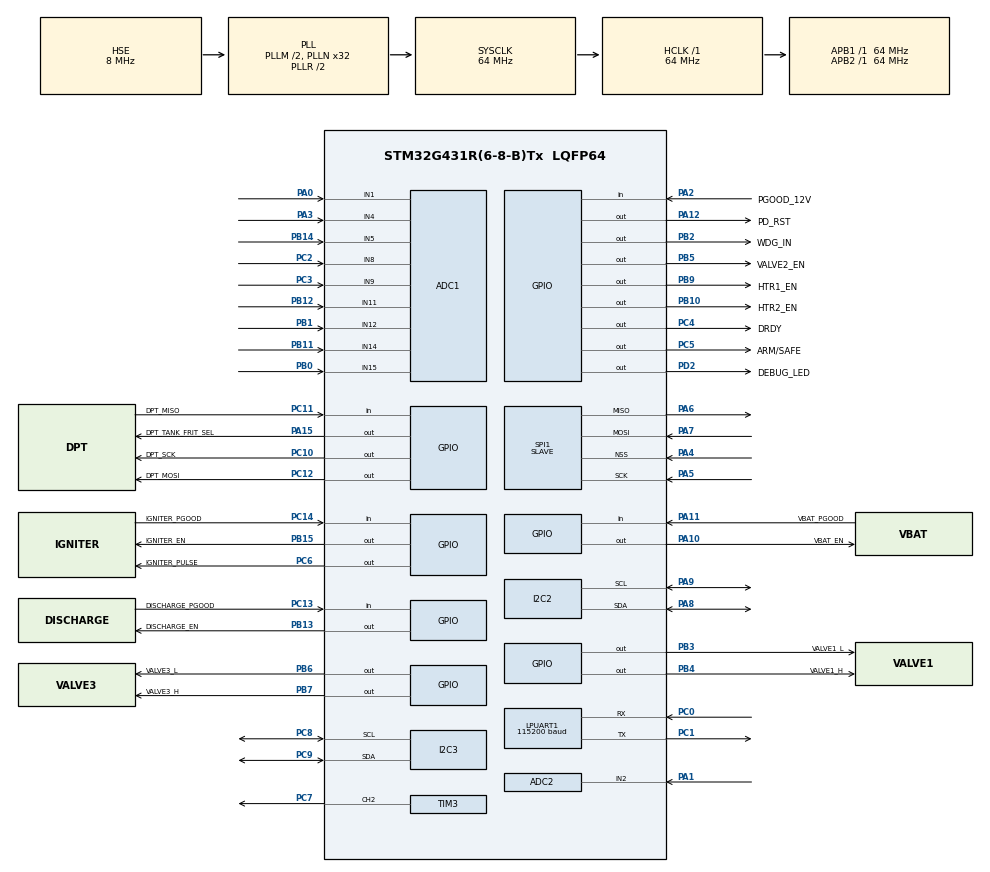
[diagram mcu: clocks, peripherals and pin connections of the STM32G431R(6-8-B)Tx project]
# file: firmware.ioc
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ADC1.Channel-0\#ChannelRegularConversion=ADC_CHANNEL_1
ADC1.ContinuousConvMode=ENABLE
ADC1.DMAAccessModeView=ENABLE
ADC1.EnableInjectedConversion=ENABLE
ADC1.InjNumberOfConversion=1
ADC1.InjectedChannel-1\#ChannelInjectedConversion=ADC_CHANNEL_4
ADC1.InjectedOffsetNumber-1\#ChannelInjectedConversion=ADC_OFFSET_NONE
ADC1.InjectedRank-1\#ChannelInjectedConversion=1
ADC1.InjectedSamplingTime-1\#ChannelInjectedConversion=ADC_SAMPLETIME_92CYCLES_5
ADC1.Mode=ADC_DUALMODE_REGSIMULT
ADC1.NbrOfConversion=1
ADC1.NbrOfConversionFlag=1
ADC1.OffsetNumber-0\#ChannelRegularConversion=ADC_OFFSET_NONE
ADC1.Rank-0\#ChannelRegularConversion=1
ADC1.Rank1_Channel=ADC_CHANNEL_4
ADC1.Rank2_Channel=ADC_CHANNEL_1
ADC1.Rank3_Channel=ADC_CHANNEL_1
ADC1.Rank4_Channel=ADC_CHANNEL_1
ADC1.SamplingTime-0\#ChannelRegularConversion=ADC_SAMPLETIME_2CYCLES_5
ADC1.master=1
ADC2.Channel-0\#ChannelRegularConversion=ADC_CHANNEL_2
ADC2.ClockPrescaler=ADC_CLOCK_SYNC_PCLK_DIV2
ADC2.ContinuousConvMode=ENABLE
ADC2.DMAAccessModeView=ENABLE
ADC2.Mode=ADC_DUALMODE_REGSIMULT
ADC2.NbrOfConversionFlag=1
ADC2.OffsetNumber-0\#ChannelRegularConversion=ADC_OFFSET_NONE
ADC2.Rank-0\#ChannelRegularConversion=1
ADC2.SamplingTime-0\#ChannelRegularConversion=ADC_SAMPLETIME_2CYCLES_5
Dma.ADC1.0.Direction=DMA_PERIPH_TO_MEMORY
Dma.ADC1.0.EventEnable=DISABLE
Dma.ADC1.0.Instance=DMA1_Channel1
Dma.ADC1.0.MemDataAlignment=DMA_MDATAALIGN_WORD
Dma.ADC1.0.MemInc=DMA_MINC_ENABLE
Dma.ADC1.0.Mode=DMA_NORMAL
Dma.ADC1.0.PeriphDataAlignment=DMA_PDATAALIGN_WORD
Dma.ADC1.0.PeriphInc=DMA_PINC_DISABLE
Dma.ADC1.0.Polarity=HAL_DMAMUX_REQ_GEN_RISING
Dma.ADC1.0.Priority=DMA_PRIORITY_VERY_HIGH
Dma.ADC1.0.RequestNumber=1
Dma.ADC1.0.SignalID=NONE
Dma.ADC1.0.SyncEnable=DISABLE
Dma.ADC1.0.SyncPolarity=HAL_DMAMUX_SYNC_NO_EVENT
Dma.ADC1.0.SyncRequestNumber=1
Dma.ADC1.0.SyncSignalID=NONE
Dma.Request0=ADC1
Dma.Request1=SPI1_RX
Dma.Request2=SPI1_TX
Dma.SPI1_RX.1.Direction=DMA_PERIPH_TO_MEMORY
Dma.SPI1_RX.1.EventEnable=DISABLE
Dma.SPI1_RX.1.Instance=DMA1_Channel2
Dma.SPI1_RX.1.MemDataAlignment=DMA_MDATAALIGN_BYTE
Dma.SPI1_RX.1.MemInc=DMA_MINC_ENABLE
Dma.SPI1_RX.1.Mode=DMA_NORMAL
Dma.SPI1_RX.1.PeriphDataAlignment=DMA_PDATAALIGN_BYTE
Dma.SPI1_RX.1.PeriphInc=DMA_PINC_DISABLE
Dma.SPI1_RX.1.Polarity=HAL_DMAMUX_REQ_GEN_RISING
Dma.SPI1_RX.1.Priority=DMA_PRIORITY_HIGH
Dma.SPI1_RX.1.RequestNumber=1
Dma.SPI1_RX.1.SignalID=NONE
Dma.SPI1_RX.1.SyncEnable=DISABLE
Dma.SPI1_RX.1.SyncPolarity=HAL_DMAMUX_SYNC_NO_EVENT
Dma.SPI1_RX.1.SyncRequestNumber=1
Dma.SPI1_RX.1.SyncSignalID=NONE
Dma.SPI1_TX.2.Direction=DMA_MEMORY_TO_PERIPH
Dma.SPI1_TX.2.EventEnable=DISABLE
Dma.SPI1_TX.2.Instance=DMA1_Channel3
Dma.SPI1_TX.2.MemDataAlignment=DMA_MDATAALIGN_BYTE
Dma.SPI1_TX.2.MemInc=DMA_MINC_ENABLE
Dma.SPI1_TX.2.Mode=DMA_NORMAL
Dma.SPI1_TX.2.PeriphDataAlignment=DMA_PDATAALIGN_BYTE
Dma.SPI1_TX.2.PeriphInc=DMA_PINC_DISABLE
Dma.SPI1_TX.2.Polarity=HAL_DMAMUX_REQ_GEN_RISING
Dma.SPI1_TX.2.Priority=DMA_PRIORITY_HIGH
Dma.SPI1_TX.2.RequestNumber=1
Dma.SPI1_TX.2.SignalID=NONE
Dma.SPI1_TX.2.SyncEnable=DISABLE
Dma.SPI1_TX.2.SyncPolarity=HAL_DMAMUX_SYNC_NO_EVENT
Dma.SPI1_TX.2.SyncRequestNumber=1
Dma.SPI1_TX.2.SyncSignalID=NONE
I2C2.Timing=0x10B17DB5
I2C3.Timing=0x10B17DB5
LPUART1.BaudRate=115200
Mcu.Family=STM32G4
Mcu.Name=STM32G431R(6-8-B)Tx
Mcu.Package=LQFP64
NVIC.DMA1_Channel1_IRQn=true\:0\:0\:false\:false\:true\:false\:true\:true
NVIC.DMA1_Channel2_IRQn=true\:0\:0\:false\:false\:true\:false\:true\:true
NVIC.DMA1_Channel3_IRQn=true\:0\:0\:false\:false\:true\:false\:true\:true
NVIC.I2C2_ER_IRQn=true\:0\:0\:false\:false\:true\:true\:true\:true
NVIC.I2C2_EV_IRQn=true\:0\:0\:false\:false\:true\:true\:true\:true
NVIC.PriorityGroup=NVIC_PRIORITYGROUP_4
NVIC.SPI1_IRQn=true\:0\:0\:false\:false\:true\:true\:true\:true
PA0.Mode=IN1-Single-Ended
PA0.Signal=ADC1_IN1
PA1.Mode=IN2-Single-Ended
PA1.Signal=ADC2_IN2
PA10.GPIO_Label=VBAT_EN
PA10.Signal=GPIO_Output
PA11.GPIO_Label=VBAT_PGOOD
PA11.Signal=GPIO_Input
PA12.GPIO_Label=PD_RST
PA12.Signal=GPIO_Output
PA13.Mode=Serial_Wire
PA13.Signal=SYS_JTMS-SWDIO
PA14.Mode=Serial_Wire
PA14.Signal=SYS_JTCK-SWCLK
PA15.GPIO_Label=DPT_TANK_FRIT_SEL
PA15.Signal=GPIO_Output
PA2.GPIO_Label=PGOOD_12V
PA2.Signal=GPIO_Input
PA3.Mode=IN4-Single-Ended
PA3.Signal=ADC1_IN4
PA4.Mode=NSS_Signal_Hard_Input
PA4.Signal=SPI1_NSS
PA5.Mode=Full_Duplex_Slave
PA5.Signal=SPI1_SCK
PA6.Mode=Full_Duplex_Slave
PA6.Signal=SPI1_MISO
PA7.Mode=Full_Duplex_Slave
PA7.Signal=SPI1_MOSI
PA8.Mode=I2C
PA8.Signal=I2C2_SDA
PA9.Mode=I2C
PA9.Signal=I2C2_SCL
PB0.Mode=IN15-Single-Ended
PB0.Signal=ADC1_IN15
PB1.Mode=IN12-Single-Ended
PB1.Signal=ADC1_IN12
PB10.GPIO_Label=HTR2_EN
PB10.Signal=GPIO_Output
PB11.Mode=IN14-Single-Ended
PB11.Signal=ADC1_IN14
PB12.Mode=IN11-Single-Ended
PB12.Signal=ADC1_IN11
PB13.GPIO_Label=DISCHARGE_EN
PB13.Signal=GPIO_Output
PB14.Mode=IN5-Single-Ended
PB14.Signal=ADC1_IN5
PB15.GPIO_Label=IGNITER_EN
PB15.Signal=GPIO_Output
PB2.GPIO_Label=WDG_IN
PB2.Signal=GPIO_Output
PB3.GPIO_Label=VALVE1_L
PB3.Signal=GPIO_Output
PB4.GPIO_Label=VALVE1_H
PB4.Signal=GPIO_Output
PB5.GPIO_Label=VALVE2_EN
PB5.Signal=GPIO_Output
PB6.GPIO_Label=VALVE3_L
PB6.Signal=GPIO_Output
PB7.GPIO_Label=VALVE3_H
PB7.Signal=GPIO_Output
PB9.GPIO_Label=HTR1_EN
PB9.Signal=GPIO_Output
PC0.Mode=Asynchronous
PC0.Signal=LPUART1_RX
PC1.Mode=Asynchronous
PC1.Signal=LPUART1_TX
PC10.GPIO_Label=DPT_SCK
PC10.Signal=GPIO_Output
PC11.GPIO_Label=DPT_MISO
PC11.Signal=GPIO_Input
PC12.GPIO_Label=DPT_MOSI
PC12.Signal=GPIO_Output
PC13.GPIO_Label=DISCHARGE_PGOOD
PC13.Signal=GPIO_Input
PC14-OSC32_IN.GPIO_Label=IGNITER_PGOOD
PC14-OSC32_IN.Signal=GPIO_Input
PC2.Mode=IN8-Single-Ended
PC2.Signal=ADC1_IN8
PC3.Mode=IN9-Single-Ended
PC3.Signal=ADC1_IN9
PC4.GPIO_Label=DRDY
PC4.Signal=GPIO_Output
PC5.GPIO_Label=ARM/SAFE
PC5.Signal=GPIO_Output
PC6.GPIO_Label=IGNITER_PULSE
PC6.Signal=GPIO_Output
PC7.Signal=S_TIM3_CH2
PC8.Mode=I2C
PC8.Signal=I2C3_SCL
PC9.Mode=I2C
PC9.Signal=I2C3_SDA
PD2.GPIO_Label=DEBUG_LED
PD2.Signal=GPIO_Output
PF0-OSC_IN.Mode=HSE-External-Oscillator
PF0-OSC_IN.Signal=RCC_OSC_IN
PF1-OSC_OUT.Mode=HSE-External-Oscillator
PF1-OSC_OUT.Signal=RCC_OSC_OUT
ProjectManager.HeapSize=0x200
ProjectManager.StackSize=0x400
ProjectManager.TargetToolchain=STM32CubeIDE
RCC.ADC12Freq_Value=64000000
RCC.AHBFreq_Value=64000000
RCC.APB1Freq_Value=64000000
RCC.APB1TimFreq_Value=64000000
RCC.APB2Freq_Value=64000000
RCC.APB2TimFreq_Value=64000000
RCC.CortexFreq_Value=64000000
RCC.EXTERNAL_CLOCK_VALUE=12288000
RCC.HCLKFreq_Value=64000000
RCC.HSE_VALUE=8000000
RCC.HSI48_VALUE=48000000
RCC.HSI_VALUE=16000000
RCC.LSE_VALUE=32768
RCC.PLLM=RCC_PLLM_DIV2
RCC.PLLN=32
RCC.PLLSourceVirtual=RCC_PLLSOURCE_HSE
RCC.SYSCLKFreq_VALUE=64000000
RCC.SYSCLKSource=RCC_SYSCLKSOURCE_PLLCLK
RCC.USBFreq_Value=64000000
RCC.VCOOutputFreq_Value=128000000
SH.S_TIM3_CH2.0=TIM3_CH2,Output Compare2 CH2
SPI1.DataSize=SPI_DATASIZE_8BIT
SPI1.Direction=SPI_DIRECTION_2LINES
SPI1.Mode=SPI_MODE_SLAVE
SPI1.VirtualNSS=VM_NSSHARD
SPI1.VirtualType=VM_SLAVE
TIM3.Channel-Output\ Compare2\ CH2=TIM_CHANNEL_2
TIM3.OCMode_2=TIM_OCMODE_TOGGLE
TIM3.PeriodNoDither=976
VP_ADC1_TempSens_Input.Mode=IN-TempSens
VP_ADC1_Vref_Input.Mode=IN-Vrefint
VP_SYS_VS_DBSignals.Mode=DisableDeadBatterySignals
board=custom

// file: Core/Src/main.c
/* USER CODE BEGIN Header */
/**
  ******************************************************************************
  * @file           : main.c
  * @brief          : Main program body
  ******************************************************************************
  * @attention
  *
  * Copyright (c) 2026 STMicroelectronics.
  * All rights reserved.
  *
  * This software is licensed under terms that can be found in the LICENSE file
  * in the root directory of this software component.
  * If no LICENSE file comes with this software, it is provided AS-IS.
  *
  ******************************************************************************
  */
/* USER CODE END Header */
#include "main.h"

/* USER CODE BEGIN Includes */
#include "app.h"
/* USER CODE END Includes */

ADC_HandleTypeDef hadc1;
ADC_HandleTypeDef hadc2;
DMA_HandleTypeDef hdma_adc1;

I2C_HandleTypeDef hi2c2;
I2C_HandleTypeDef hi2c3;

UART_HandleTypeDef hlpuart1;

SPI_HandleTypeDef hspi1;
DMA_HandleTypeDef hdma_spi1_rx;
DMA_HandleTypeDef hdma_spi1_tx;

TIM_HandleTypeDef htim3;

/* USER CODE BEGIN PV */
int a;
/* USER CODE END PV */

void SystemClock_Config(void);
static void MX_GPIO_Init(void);
static void MX_DMA_Init(void);
static void MX_ADC1_Init(void);
static void MX_I2C2_Init(void);
static void MX_I2C3_Init(void);
static void MX_SPI1_Init(void);
static void MX_LPUART1_UART_Init(void);
static void MX_TIM3_Init(void);
static void MX_ADC2_Init(void);

int main(void)
{

  /* MCU Configuration--------------------------------------------------------*/

  /* Reset of all peripherals, Initializes the Flash interface and the Systick. */
  HAL_Init();

  /* Configure the system clock */
  SystemClock_Config();

  /* Initialize all configured peripherals */
  MX_GPIO_Init();
  MX_DMA_Init();
  MX_ADC1_Init();
  MX_I2C2_Init();
  MX_I2C3_Init();
  MX_SPI1_Init();
  MX_LPUART1_UART_Init();
  MX_TIM3_Init();
  MX_ADC2_Init();
  /* USER CODE BEGIN 2 */
  app_init();

  /* USER CODE END 2 */

  /* Infinite loop */
  while (1)
  {

    /* USER CODE BEGIN 3 */
    app_run_once();
  }
  /* USER CODE END 3 */
}

void SystemClock_Config(void)
{
  RCC_OscInitTypeDef RCC_OscInitStruct = {0};
  RCC_ClkInitTypeDef RCC_ClkInitStruct = {0};

  /** Configure the main internal regulator output voltage
  */
  HAL_PWREx_ControlVoltageScaling(PWR_REGULATOR_VOLTAGE_SCALE1);

  /** Initializes the RCC Oscillators according to the specified parameters
  * in the RCC_OscInitTypeDef structure.
  */
  RCC_OscInitStruct.OscillatorType = RCC_OSCILLATORTYPE_HSE;
  RCC_OscInitStruct.HSEState = RCC_HSE_ON;
  RCC_OscInitStruct.PLL.PLLState = RCC_PLL_ON;
  RCC_OscInitStruct.PLL.PLLSource = RCC_PLLSOURCE_HSE;
  RCC_OscInitStruct.PLL.PLLM = RCC_PLLM_DIV2;
  RCC_OscInitStruct.PLL.PLLN = 32;
  RCC_OscInitStruct.PLL.PLLP = RCC_PLLP_DIV2;
  RCC_OscInitStruct.PLL.PLLQ = RCC_PLLQ_DIV2;
  RCC_OscInitStruct.PLL.PLLR = RCC_PLLR_DIV2;
  if (HAL_RCC_OscConfig(&RCC_OscInitStruct) != HAL_OK)
  {
    Error_Handler();
  }

  /** Initializes the CPU, AHB and APB buses clocks
  */
  RCC_ClkInitStruct.ClockType = RCC_CLOCKTYPE_HCLK|RCC_CLOCKTYPE_SYSCLK
                              |RCC_CLOCKTYPE_PCLK1|RCC_CLOCKTYPE_PCLK2;
  RCC_ClkInitStruct.SYSCLKSource = RCC_SYSCLKSOURCE_PLLCLK;
  RCC_ClkInitStruct.AHBCLKDivider = RCC_SYSCLK_DIV1;
  RCC_ClkInitStruct.APB1CLKDivider = RCC_HCLK_DIV1;
  RCC_ClkInitStruct.APB2CLKDivider = RCC_HCLK_DIV1;

  if (HAL_RCC_ClockConfig(&RCC_ClkInitStruct, FLASH_LATENCY_2) != HAL_OK)
  {
    Error_Handler();
  }
}

static void MX_ADC1_Init(void)
{

  ADC_MultiModeTypeDef multimode = {0};
  ADC_ChannelConfTypeDef sConfig = {0};
  ADC_InjectionConfTypeDef sConfigInjected = {0};

  /** Common config
  */
  hadc1.Instance = ADC1;
  hadc1.Init.ClockPrescaler = ADC_CLOCK_SYNC_PCLK_DIV2;
  hadc1.Init.Resolution = ADC_RESOLUTION_12B;
  hadc1.Init.DataAlign = ADC_DATAALIGN_RIGHT;
  hadc1.Init.GainCompensation = 0;
  hadc1.Init.ScanConvMode = ADC_SCAN_DISABLE;
  hadc1.Init.EOCSelection = ADC_EOC_SINGLE_CONV;
  hadc1.Init.LowPowerAutoWait = DISABLE;
  hadc1.Init.ContinuousConvMode = ENABLE;
  hadc1.Init.NbrOfConversion = 1;
  hadc1.Init.DiscontinuousConvMode = DISABLE;
  hadc1.Init.ExternalTrigConv = ADC_SOFTWARE_START;
  hadc1.Init.ExternalTrigConvEdge = ADC_EXTERNALTRIGCONVEDGE_NONE;
  hadc1.Init.DMAContinuousRequests = DISABLE;
  hadc1.Init.Overrun = ADC_OVR_DATA_PRESERVED;
  hadc1.Init.OversamplingMode = DISABLE;
  if (HAL_ADC_Init(&hadc1) != HAL_OK)
  {
    Error_Handler();
  }

  /** Configure the ADC multi-mode
  */
  multimode.Mode = ADC_DUALMODE_REGSIMULT;
  multimode.DMAAccessMode = ADC_DMAACCESSMODE_12_10_BITS;
  multimode.TwoSamplingDelay = ADC_TWOSAMPLINGDELAY_1CYCLE;
  if (HAL_ADCEx_MultiModeConfigChannel(&hadc1, &multimode) != HAL_OK)
  {
    Error_Handler();
  }

  /** Configure Regular Channel
  */
  sConfig.Channel = ADC_CHANNEL_1;
  sConfig.Rank = ADC_REGULAR_RANK_1;
  sConfig.SamplingTime = ADC_SAMPLETIME_2CYCLES_5;
  sConfig.SingleDiff = ADC_SINGLE_ENDED;
  sConfig.OffsetNumber = ADC_OFFSET_NONE;
  sConfig.Offset = 0;
  if (HAL_ADC_ConfigChannel(&hadc1, &sConfig) != HAL_OK)
  {
    Error_Handler();
  }

  /** Configure Injected Channel
  */
  sConfigInjected.InjectedChannel = ADC_CHANNEL_4;
  sConfigInjected.InjectedRank = ADC_INJECTED_RANK_1;
  sConfigInjected.InjectedSamplingTime = ADC_SAMPLETIME_92CYCLES_5;
  sConfigInjected.InjectedSingleDiff = ADC_SINGLE_ENDED;
  sConfigInjected.InjectedOffsetNumber = ADC_OFFSET_NONE;
  sConfigInjected.InjectedOffset = 0;
  sConfigInjected.InjectedNbrOfConversion = 1;
  sConfigInjected.InjectedDiscontinuousConvMode = DISABLE;
  sConfigInjected.AutoInjectedConv = DISABLE;
  sConfigInjected.QueueInjectedContext = DISABLE;
  sConfigInjected.ExternalTrigInjecConv = ADC_INJECTED_SOFTWARE_START;
  sConfigInjected.ExternalTrigInjecConvEdge = ADC_EXTERNALTRIGINJECCONV_EDGE_NONE;
  sConfigInjected.InjecOversamplingMode = DISABLE;
  if (HAL_ADCEx_InjectedConfigChannel(&hadc1, &sConfigInjected) != HAL_OK)
  {
    Error_Handler();
  }

}

static void MX_ADC2_Init(void)
{

  ADC_ChannelConfTypeDef sConfig = {0};

  /** Common config
  */
  hadc2.Instance = ADC2;
  hadc2.Init.ClockPrescaler = ADC_CLOCK_SYNC_PCLK_DIV2;
  hadc2.Init.Resolution = ADC_RESOLUTION_12B;
  hadc2.Init.DataAlign = ADC_DATAALIGN_RIGHT;
  hadc2.Init.GainCompensation = 0;
  hadc2.Init.ScanConvMode = ADC_SCAN_DISABLE;
  hadc2.Init.EOCSelection = ADC_EOC_SINGLE_CONV;
  hadc2.Init.LowPowerAutoWait = DISABLE;
  hadc2.Init.ContinuousConvMode = ENABLE;
  hadc2.Init.NbrOfConversion = 1;
  hadc2.Init.DiscontinuousConvMode = DISABLE;
  hadc2.Init.DMAContinuousRequests = DISABLE;
  hadc2.Init.Overrun = ADC_OVR_DATA_PRESERVED;
  hadc2.Init.OversamplingMode = DISABLE;
  if (HAL_ADC_Init(&hadc2) != HAL_OK)
  {
    Error_Handler();
  }

  /** Configure Regular Channel
  */
  sConfig.Channel = ADC_CHANNEL_2;
  sConfig.Rank = ADC_REGULAR_RANK_1;
  sConfig.SamplingTime = ADC_SAMPLETIME_2CYCLES_5;
  sConfig.SingleDiff = ADC_SINGLE_ENDED;
  sConfig.OffsetNumber = ADC_OFFSET_NONE;
  sConfig.Offset = 0;
  if (HAL_ADC_ConfigChannel(&hadc2, &sConfig) != HAL_OK)
  {
    Error_Handler();
  }

}

static void MX_I2C2_Init(void)
{

  hi2c2.Instance = I2C2;
  hi2c2.Init.Timing = 0x10B17DB5;
  hi2c2.Init.OwnAddress1 = 0;
  hi2c2.Init.AddressingMode = I2C_ADDRESSINGMODE_7BIT;
  hi2c2.Init.DualAddressMode = I2C_DUALADDRESS_DISABLE;
  hi2c2.Init.OwnAddress2 = 0;
  hi2c2.Init.OwnAddress2Masks = I2C_OA2_NOMASK;
  hi2c2.Init.GeneralCallMode = I2C_GENERALCALL_DISABLE;
  hi2c2.Init.NoStretchMode = I2C_NOSTRETCH_DISABLE;
  if (HAL_I2C_Init(&hi2c2) != HAL_OK)
  {
    Error_Handler();
  }

  /** Configure Analogue filter
  */
  if (HAL_I2CEx_ConfigAnalogFilter(&hi2c2, I2C_ANALOGFILTER_ENABLE) != HAL_OK)
  {
    Error_Handler();
  }

  /** Configure Digital filter
  */
  if (HAL_I2CEx_ConfigDigitalFilter(&hi2c2, 0) != HAL_OK)
  {
    Error_Handler();
  }

}

static void MX_I2C3_Init(void)
{

  hi2c3.Instance = I2C3;
  hi2c3.Init.Timing = 0x10B17DB5;
  hi2c3.Init.OwnAddress1 = 0;
  hi2c3.Init.AddressingMode = I2C_ADDRESSINGMODE_7BIT;
  hi2c3.Init.DualAddressMode = I2C_DUALADDRESS_DISABLE;
  hi2c3.Init.OwnAddress2 = 0;
  hi2c3.Init.OwnAddress2Masks = I2C_OA2_NOMASK;
  hi2c3.Init.GeneralCallMode = I2C_GENERALCALL_DISABLE;
  hi2c3.Init.NoStretchMode = I2C_NOSTRETCH_DISABLE;
  if (HAL_I2C_Init(&hi2c3) != HAL_OK)
  {
    Error_Handler();
  }

  /** Configure Analogue filter
  */
  if (HAL_I2CEx_ConfigAnalogFilter(&hi2c3, I2C_ANALOGFILTER_ENABLE) != HAL_OK)
  {
    Error_Handler();
  }

  /** Configure Digital filter
  */
  if (HAL_I2CEx_ConfigDigitalFilter(&hi2c3, 0) != HAL_OK)
  {
    Error_Handler();
  }

}

static void MX_LPUART1_UART_Init(void)
{

  hlpuart1.Instance = LPUART1;
  hlpuart1.Init.BaudRate = 115200;
  hlpuart1.Init.WordLength = UART_WORDLENGTH_8B;
  hlpuart1.Init.StopBits = UART_STOPBITS_1;
  hlpuart1.Init.Parity = UART_PARITY_NONE;
  hlpuart1.Init.Mode = UART_MODE_TX_RX;
  hlpuart1.Init.HwFlowCtl = UART_HWCONTROL_NONE;
  hlpuart1.Init.OneBitSampling = UART_ONE_BIT_SAMPLE_DISABLE;
  hlpuart1.Init.ClockPrescaler = UART_PRESCALER_DIV1;
  hlpuart1.AdvancedInit.AdvFeatureInit = UART_ADVFEATURE_NO_INIT;
  if (HAL_UART_Init(&hlpuart1) != HAL_OK)
  {
    Error_Handler();
  }
  if (HAL_UARTEx_SetTxFifoThreshold(&hlpuart1, UART_TXFIFO_THRESHOLD_1_8) != HAL_OK)
  {
    Error_Handler();
  }
  if (HAL_UARTEx_SetRxFifoThreshold(&hlpuart1, UART_RXFIFO_THRESHOLD_1_8) != HAL_OK)
  {
    Error_Handler();
  }
  if (HAL_UARTEx_DisableFifoMode(&hlpuart1) != HAL_OK)
  {
    Error_Handler();
  }

}

static void MX_SPI1_Init(void)
{

  /* SPI1 parameter configuration*/
  hspi1.Instance = SPI1;
  hspi1.Init.Mode = SPI_MODE_SLAVE;
  hspi1.Init.Direction = SPI_DIRECTION_2LINES;
  hspi1.Init.DataSize = SPI_DATASIZE_8BIT;
  hspi1.Init.CLKPolarity = SPI_POLARITY_LOW;
  hspi1.Init.CLKPhase = SPI_PHASE_1EDGE;
  hspi1.Init.NSS = SPI_NSS_HARD_INPUT;
  hspi1.Init.FirstBit = SPI_FIRSTBIT_MSB;
  hspi1.Init.TIMode = SPI_TIMODE_DISABLE;
  hspi1.Init.CRCCalculation = SPI_CRCCALCULATION_DISABLE;
  hspi1.Init.CRCPolynomial = 7;
  hspi1.Init.CRCLength = SPI_CRC_LENGTH_DATASIZE;
  hspi1.Init.NSSPMode = SPI_NSS_PULSE_DISABLE;
  if (HAL_SPI_Init(&hspi1) != HAL_OK)
  {
    Error_Handler();
  }

}

static void MX_TIM3_Init(void)
{

  TIM_MasterConfigTypeDef sMasterConfig = {0};
  TIM_OC_InitTypeDef sConfigOC = {0};

  htim3.Instance = TIM3;
  htim3.Init.Prescaler = 0;
  htim3.Init.CounterMode = TIM_COUNTERMODE_UP;
  htim3.Init.Period = 976;
  htim3.Init.ClockDivision = TIM_CLOCKDIVISION_DIV1;
  htim3.Init.AutoReloadPreload = TIM_AUTORELOAD_PRELOAD_DISABLE;
  if (HAL_TIM_OC_Init(&htim3) != HAL_OK)
  {
    Error_Handler();
  }
  sMasterConfig.MasterOutputTrigger = TIM_TRGO_RESET;
  sMasterConfig.MasterSlaveMode = TIM_MASTERSLAVEMODE_DISABLE;
  if (HAL_TIMEx_MasterConfigSynchronization(&htim3, &sMasterConfig) != HAL_OK)
  {
    Error_Handler();
  }
  sConfigOC.OCMode = TIM_OCMODE_TOGGLE;
  sConfigOC.Pulse = 0;
  sConfigOC.OCPolarity = TIM_OCPOLARITY_HIGH;
  sConfigOC.OCFastMode = TIM_OCFAST_DISABLE;
  if (HAL_TIM_OC_ConfigChannel(&htim3, &sConfigOC, TIM_CHANNEL_2) != HAL_OK)
  {
    Error_Handler();
  }
  HAL_TIM_MspPostInit(&htim3);

}

static void MX_DMA_Init(void)
{

  /* DMA controller clock enable */
  __HAL_RCC_DMAMUX1_CLK_ENABLE();
  __HAL_RCC_DMA1_CLK_ENABLE();

  /* DMA interrupt init */
  /* DMA1_Channel1_IRQn interrupt configuration */
  HAL_NVIC_SetPriority(DMA1_Channel1_IRQn, 0, 0);
  HAL_NVIC_EnableIRQ(DMA1_Channel1_IRQn);
  /* DMA1_Channel2_IRQn interrupt configuration */
  HAL_NVIC_SetPriority(DMA1_Channel2_IRQn, 0, 0);
  HAL_NVIC_EnableIRQ(DMA1_Channel2_IRQn);
  /* DMA1_Channel3_IRQn interrupt configuration */
  HAL_NVIC_SetPriority(DMA1_Channel3_IRQn, 0, 0);
  HAL_NVIC_EnableIRQ(DMA1_Channel3_IRQn);

}

static void MX_GPIO_Init(void)
{
  GPIO_InitTypeDef GPIO_InitStruct = {0};

  /* GPIO Ports Clock Enable */
  __HAL_RCC_GPIOC_CLK_ENABLE();
  __HAL_RCC_GPIOF_CLK_ENABLE();
  __HAL_RCC_GPIOA_CLK_ENABLE();
  __HAL_RCC_GPIOB_CLK_ENABLE();
  __HAL_RCC_GPIOD_CLK_ENABLE();

  /*Configure GPIO pin Output Level */
  HAL_GPIO_WritePin(GPIOC, DRDY_Pin|ARM_SAFE_Pin|IGNITER_PULSE_Pin|DPT_SCK_Pin
                          |DPT_MOSI_Pin, GPIO_PIN_RESET);

  /*Configure GPIO pin Output Level */
  HAL_GPIO_WritePin(GPIOB, WDG_IN_Pin|HTR2_EN_Pin|DISCHARGE_EN_Pin|IGNITER_EN_Pin
                          |VALVE1_L_Pin|VALVE1_H_Pin|VALVE2_EN_Pin|VALVE3_L_Pin
                          |VALVE3_H_Pin|HTR1_EN_Pin, GPIO_PIN_RESET);

  /*Configure GPIO pin Output Level */
  HAL_GPIO_WritePin(GPIOA, VBAT_EN_Pin|PD_RST_Pin|DPT_TANK_FRIT_SEL_Pin, GPIO_PIN_RESET);

  /*Configure GPIO pin Output Level */
  HAL_GPIO_WritePin(DEBUG_LED_GPIO_Port, DEBUG_LED_Pin, GPIO_PIN_RESET);

  /*Configure GPIO pins : DISCHARGE_PGOOD_Pin IGNITER_PGOOD_Pin DPT_MISO_Pin */
  GPIO_InitStruct.Pin = DISCHARGE_PGOOD_Pin|IGNITER_PGOOD_Pin|DPT_MISO_Pin;
  GPIO_InitStruct.Mode = GPIO_MODE_INPUT;
  GPIO_InitStruct.Pull = GPIO_NOPULL;
  HAL_GPIO_Init(GPIOC, &GPIO_InitStruct);

  /*Configure GPIO pins : PGOOD_12V_Pin VBAT_PGOOD_Pin */
  GPIO_InitStruct.Pin = PGOOD_12V_Pin|VBAT_PGOOD_Pin;
  GPIO_InitStruct.Mode = GPIO_MODE_INPUT;
  GPIO_InitStruct.Pull = GPIO_NOPULL;
  HAL_GPIO_Init(GPIOA, &GPIO_InitStruct);

  /*Configure GPIO pins : DRDY_Pin ARM_SAFE_Pin IGNITER_PULSE_Pin DPT_SCK_Pin
                           DPT_MOSI_Pin */
  GPIO_InitStruct.Pin = DRDY_Pin|ARM_SAFE_Pin|IGNITER_PULSE_Pin|DPT_SCK_Pin
                          |DPT_MOSI_Pin;
  GPIO_InitStruct.Mode = GPIO_MODE_OUTPUT_PP;
  GPIO_InitStruct.Pull = GPIO_NOPULL;
  GPIO_InitStruct.Speed = GPIO_SPEED_FREQ_LOW;
  HAL_GPIO_Init(GPIOC, &GPIO_InitStruct);

  /*Configure GPIO pins : WDG_IN_Pin HTR2_EN_Pin DISCHARGE_EN_Pin IGNITER_EN_Pin
                           VALVE1_L_Pin VALVE1_H_Pin VALVE2_EN_Pin VALVE3_L_Pin
                           VALVE3_H_Pin HTR1_EN_Pin */
  GPIO_InitStruct.Pin = WDG_IN_Pin|HTR2_EN_Pin|DISCHARGE_EN_Pin|IGNITER_EN_Pin
                          |VALVE1_L_Pin|VALVE1_H_Pin|VALVE2_EN_Pin|VALVE3_L_Pin
                          |VALVE3_H_Pin|HTR1_EN_Pin;
  GPIO_InitStruct.Mode = GPIO_MODE_OUTPUT_PP;
  GPIO_InitStruct.Pull = GPIO_NOPULL;
  GPIO_InitStruct.Speed = GPIO_SPEED_FREQ_LOW;
  HAL_GPIO_Init(GPIOB, &GPIO_InitStruct);

  /*Configure GPIO pins : VBAT_EN_Pin PD_RST_Pin DPT_TANK_FRIT_SEL_Pin */
  GPIO_InitStruct.Pin = VBAT_EN_Pin|PD_RST_Pin|DPT_TANK_FRIT_SEL_Pin;
  GPIO_InitStruct.Mode = GPIO_MODE_OUTPUT_PP;
  GPIO_InitStruct.Pull = GPIO_NOPULL;
  GPIO_InitStruct.Speed = GPIO_SPEED_FREQ_LOW;
  HAL_GPIO_Init(GPIOA, &GPIO_InitStruct);

  /*Configure GPIO pin : DEBUG_LED_Pin */
  GPIO_InitStruct.Pin = DEBUG_LED_Pin;
  GPIO_InitStruct.Mode = GPIO_MODE_OUTPUT_PP;
  GPIO_InitStruct.Pull = GPIO_NOPULL;
  GPIO_InitStruct.Speed = GPIO_SPEED_FREQ_LOW;
  HAL_GPIO_Init(DEBUG_LED_GPIO_Port, &GPIO_InitStruct);

}

void Error_Handler(void)
{
  __disable_irq();
  while (1)
  {
  }
}
